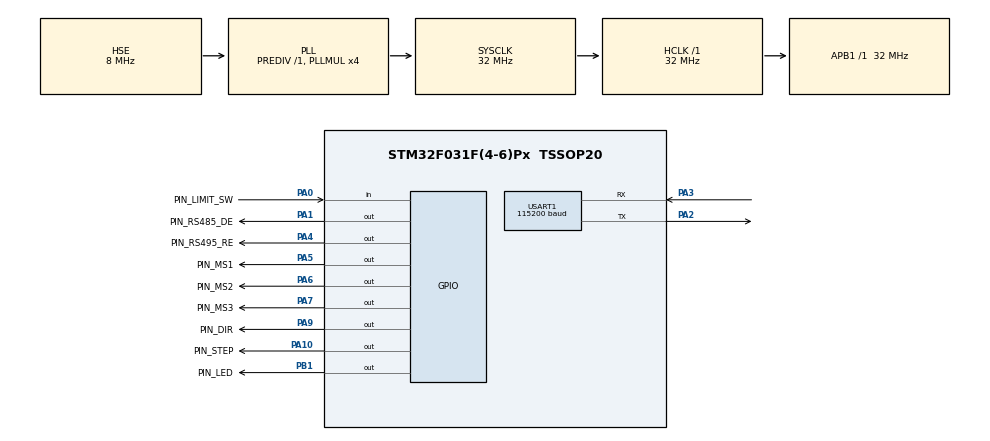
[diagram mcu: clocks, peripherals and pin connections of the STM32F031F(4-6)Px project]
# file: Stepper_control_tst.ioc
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Dma.Request0=USART1_RX
Dma.USART1_RX.0.Direction=DMA_PERIPH_TO_MEMORY
Dma.USART1_RX.0.Instance=DMA1_Channel3
Dma.USART1_RX.0.MemDataAlignment=DMA_MDATAALIGN_BYTE
Dma.USART1_RX.0.MemInc=DMA_MINC_ENABLE
Dma.USART1_RX.0.Mode=DMA_CIRCULAR
Dma.USART1_RX.0.PeriphDataAlignment=DMA_PDATAALIGN_BYTE
Dma.USART1_RX.0.PeriphInc=DMA_PINC_DISABLE
Dma.USART1_RX.0.Priority=DMA_PRIORITY_LOW
Mcu.Family=STM32F0
Mcu.Name=STM32F031F(4-6)Px
Mcu.Package=TSSOP20
NVIC.DMA1_Channel2_3_IRQn=true\:0\:0\:false\:false\:true\:false\:true\:true
NVIC.TIM2_IRQn=true\:0\:0\:false\:false\:true\:true\:true\:true
PA0.GPIO_Label=PIN_LIMIT_SW
PA0.Signal=GPIO_Input
PA1.GPIO_Label=PIN_RS485_DE
PA1.Signal=GPIO_Output
PA10.GPIO_Label=PIN_STEP
PA10.Signal=GPIO_Output
PA13.Mode=Serial_Wire
PA13.Signal=SYS_SWDIO
PA14.Mode=Serial_Wire
PA14.Signal=SYS_SWCLK
PA2.Mode=Asynchronous
PA2.Signal=USART1_TX
PA3.Mode=Asynchronous
PA3.Signal=USART1_RX
PA4.GPIO_Label=PIN_RS495_RE
PA4.Signal=GPIO_Output
PA5.GPIO_Label=PIN_MS1
PA5.Signal=GPIO_Output
PA6.GPIO_Label=PIN_MS2
PA6.Signal=GPIO_Output
PA7.GPIO_Label=PIN_MS3
PA7.Signal=GPIO_Output
PA9.GPIO_Label=PIN_DIR
PA9.Signal=GPIO_Output
PB1.GPIO_Label=PIN_LED
PB1.Signal=GPIO_Output
PF0-OSC_IN.Mode=HSE-External-Oscillator
PF0-OSC_IN.Signal=RCC_OSC_IN
PF1-OSC_OUT.Mode=HSE-External-Oscillator
PF1-OSC_OUT.Signal=RCC_OSC_OUT
ProjectManager.HeapSize=0x200
ProjectManager.StackSize=0x400
ProjectManager.TargetToolchain=STM32CubeIDE
RCC.AHBFreq_Value=32000000
RCC.APB1Freq_Value=32000000
RCC.APB1TimFreq_Value=32000000
RCC.HCLKFreq_Value=32000000
RCC.PLLMUL=RCC_PLL_MUL4
RCC.PLLSourceVirtual=RCC_PLLSOURCE_HSE
RCC.SYSCLKFreq_VALUE=32000000
RCC.SYSCLKSource=RCC_SYSCLKSOURCE_PLLCLK
TIM2.AutoReloadPreload=TIM_AUTORELOAD_PRELOAD_ENABLE
TIM2.Period=160
TIM2.Prescaler=100
USART1.BaudRate=115200
USART1.VirtualMode-Asynchronous=VM_ASYNC
VP_ADC_Vbat_Input.Mode=IN-Vbat
VP_TIM2_VS_ClockSourceINT.Mode=Internal
board=custom

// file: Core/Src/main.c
/* USER CODE BEGIN Header */
/**
  ******************************************************************************
  * @file           : main.c
  * @brief          : Main program body
  ******************************************************************************
  * @attention
  *
  * Copyright (c) 2023 STMicroelectronics.
  * All rights reserved.
  *
  * This software is licensed under terms that can be found in the LICENSE file
  * in the root directory of this software component.
  * If no LICENSE file comes with this software, it is provided AS-IS.
  *
  ******************************************************************************
  */
/* USER CODE END Header */
#include "main.h"

/* USER CODE BEGIN Includes */
#include <stdbool.h>

#include "cmd.h"
#include "stepper_control.h"
#include "debug_FZ.h"

/* USER CODE END Includes */

ADC_HandleTypeDef hadc;

TIM_HandleTypeDef htim2;

// UART_HandleTypeDef huart1;
DMA_HandleTypeDef hdma_usart1_rx;

void SystemClock_Config(void);
static void MX_GPIO_Init(void);
static void MX_DMA_Init(void);
// static void MX_USART1_UART_Init(void);
static void MX_ADC_Init(void);
static void MX_TIM2_Init(void);

int main(void)
{
  /* USER CODE BEGIN 1 */
    /* Reset of all peripherals, Initializes the Flash interface and the Systick. */
  HAL_Init();

  /* Configure the system clock */
  SystemClock_Config();

  /* Initialize all configured peripherals */
  MX_GPIO_Init();
  MX_DMA_Init();
  MX_USART1_UART_Init();
  MX_ADC_Init();
  MX_TIM2_Init();

  DMA_init();

  stepper_init(MICROSTEP_1_8);

  HAL_TIM_Base_Start_IT(&htim2);

  HAL_GPIO_WritePin(PIN_LED_GPIO_Port, PIN_LED_Pin, GPIO_PIN_SET);
  HAL_Delay(50);
  HAL_GPIO_WritePin(PIN_LED_GPIO_Port, PIN_LED_Pin, GPIO_PIN_RESET);

  /* Infinite loop */
  while (1)
  {
    Parse_CMD(CMD_recv);

  }
}

void SystemClock_Config(void)
{
  RCC_OscInitTypeDef RCC_OscInitStruct = {0};
  RCC_ClkInitTypeDef RCC_ClkInitStruct = {0};
  RCC_PeriphCLKInitTypeDef PeriphClkInit = {0};

  /** Initializes the RCC Oscillators according to the specified parameters
  * in the RCC_OscInitTypeDef structure.
  */
  RCC_OscInitStruct.OscillatorType = RCC_OSCILLATORTYPE_HSI14|RCC_OSCILLATORTYPE_HSE;
  RCC_OscInitStruct.HSEState = RCC_HSE_ON;
  RCC_OscInitStruct.HSI14State = RCC_HSI14_ON;
  RCC_OscInitStruct.HSI14CalibrationValue = 16;
  RCC_OscInitStruct.PLL.PLLState = RCC_PLL_ON;
  RCC_OscInitStruct.PLL.PLLSource = RCC_PLLSOURCE_HSE;
  RCC_OscInitStruct.PLL.PLLMUL = RCC_PLL_MUL4;
  RCC_OscInitStruct.PLL.PREDIV = RCC_PREDIV_DIV1;
  if (HAL_RCC_OscConfig(&RCC_OscInitStruct) != HAL_OK)
  {
    Error_Handler();
  }

  /** Initializes the CPU, AHB and APB buses clocks
  */
  RCC_ClkInitStruct.ClockType = RCC_CLOCKTYPE_HCLK|RCC_CLOCKTYPE_SYSCLK
                              |RCC_CLOCKTYPE_PCLK1;
  RCC_ClkInitStruct.SYSCLKSource = RCC_SYSCLKSOURCE_PLLCLK;
  RCC_ClkInitStruct.AHBCLKDivider = RCC_SYSCLK_DIV1;
  RCC_ClkInitStruct.APB1CLKDivider = RCC_HCLK_DIV1;

  if (HAL_RCC_ClockConfig(&RCC_ClkInitStruct, FLASH_LATENCY_1) != HAL_OK)
  {
    Error_Handler();
  }
  PeriphClkInit.PeriphClockSelection = RCC_PERIPHCLK_USART1;
  PeriphClkInit.Usart1ClockSelection = RCC_USART1CLKSOURCE_PCLK1;
  if (HAL_RCCEx_PeriphCLKConfig(&PeriphClkInit) != HAL_OK)
  {
    Error_Handler();
  }
}

static void MX_ADC_Init(void)
{

  ADC_ChannelConfTypeDef sConfig = {0};

  /** Configure the global features of the ADC (Clock, Resolution, Data Alignment and number of conversion)
  */
  hadc.Instance = ADC1;
  hadc.Init.ClockPrescaler = ADC_CLOCK_ASYNC_DIV1;
  hadc.Init.Resolution = ADC_RESOLUTION_12B;
  hadc.Init.DataAlign = ADC_DATAALIGN_RIGHT;
  hadc.Init.ScanConvMode = ADC_SCAN_DIRECTION_FORWARD;
  hadc.Init.EOCSelection = ADC_EOC_SINGLE_CONV;
  hadc.Init.LowPowerAutoWait = DISABLE;
  hadc.Init.LowPowerAutoPowerOff = DISABLE;
  hadc.Init.ContinuousConvMode = DISABLE;
  hadc.Init.DiscontinuousConvMode = DISABLE;
  hadc.Init.ExternalTrigConv = ADC_SOFTWARE_START;
  hadc.Init.ExternalTrigConvEdge = ADC_EXTERNALTRIGCONVEDGE_NONE;
  hadc.Init.DMAContinuousRequests = DISABLE;
  hadc.Init.Overrun = ADC_OVR_DATA_PRESERVED;
  if (HAL_ADC_Init(&hadc) != HAL_OK)
  {
    Error_Handler();
  }

  /** Configure for the selected ADC regular channel to be converted.
  */
  sConfig.Channel = ADC_CHANNEL_VBAT;
  sConfig.Rank = ADC_RANK_CHANNEL_NUMBER;
  sConfig.SamplingTime = ADC_SAMPLETIME_1CYCLE_5;
  if (HAL_ADC_ConfigChannel(&hadc, &sConfig) != HAL_OK)
  {
    Error_Handler();
  }

}

static void MX_TIM2_Init(void)
{

  TIM_ClockConfigTypeDef sClockSourceConfig = {0};
  TIM_MasterConfigTypeDef sMasterConfig = {0};

  htim2.Instance = TIM2;
  htim2.Init.Prescaler = 50;
  htim2.Init.CounterMode = TIM_COUNTERMODE_UP;
  htim2.Init.Period = 160;
  htim2.Init.ClockDivision = TIM_CLOCKDIVISION_DIV1;
  htim2.Init.AutoReloadPreload = TIM_AUTORELOAD_PRELOAD_ENABLE;
  if (HAL_TIM_Base_Init(&htim2) != HAL_OK) {
    Error_Handler();
  }

  sClockSourceConfig.ClockSource = TIM_CLOCKSOURCE_INTERNAL;

  if (HAL_TIM_ConfigClockSource(&htim2, &sClockSourceConfig) != HAL_OK) {
    Error_Handler();
  }

  sMasterConfig.MasterOutputTrigger = TIM_TRGO_RESET;
  sMasterConfig.MasterSlaveMode = TIM_MASTERSLAVEMODE_DISABLE;

  if (HAL_TIMEx_MasterConfigSynchronization(&htim2, &sMasterConfig) != HAL_OK) {
    Error_Handler();
  }

}

static void MX_DMA_Init(void)
{

  /* DMA controller clock enable */
  __HAL_RCC_DMA1_CLK_ENABLE();

  /* DMA interrupt init */
  /* DMA1_Channel2_3_IRQn interrupt configuration */
  HAL_NVIC_SetPriority(DMA1_Channel2_3_IRQn, 0, 0);
  HAL_NVIC_EnableIRQ(DMA1_Channel2_3_IRQn);

}

static void MX_GPIO_Init(void)
{
  GPIO_InitTypeDef GPIO_InitStruct = {0};

  /* GPIO Ports Clock Enable */
  __HAL_RCC_GPIOF_CLK_ENABLE();
  __HAL_RCC_GPIOA_CLK_ENABLE();
  __HAL_RCC_GPIOB_CLK_ENABLE();

  /*Configure GPIO pin Output Level */
  HAL_GPIO_WritePin(GPIOA, PIN_RS485_DE_Pin|PIN_RS495_RE_Pin|PIN_MS1_Pin|PIN_MS2_Pin
                          |PIN_MS3_Pin|PIN_DIR_Pin|PIN_STEP_Pin, GPIO_PIN_RESET);

  /*Configure GPIO pin Output Level */
  HAL_GPIO_WritePin(PIN_LED_GPIO_Port, PIN_LED_Pin, GPIO_PIN_RESET);

  /*Configure GPIO pin : PIN_LIMIT_SW_Pin */
  GPIO_InitStruct.Pin = PIN_LIMIT_SW_Pin;
  GPIO_InitStruct.Mode = GPIO_MODE_INPUT;
  GPIO_InitStruct.Pull = GPIO_NOPULL;
  HAL_GPIO_Init(PIN_LIMIT_SW_GPIO_Port, &GPIO_InitStruct);

  /*Configure GPIO pins : PIN_RS485_DE_Pin PIN_RS495_RE_Pin PIN_MS1_Pin PIN_MS2_Pin
                           PIN_MS3_Pin PIN_DIR_Pin PIN_STEP_Pin */
  GPIO_InitStruct.Pin = PIN_RS485_DE_Pin|PIN_RS495_RE_Pin|PIN_MS1_Pin|PIN_MS2_Pin
                          |PIN_MS3_Pin|PIN_DIR_Pin|PIN_STEP_Pin;
  GPIO_InitStruct.Mode = GPIO_MODE_OUTPUT_PP;
  GPIO_InitStruct.Pull = GPIO_NOPULL;
  GPIO_InitStruct.Speed = GPIO_SPEED_FREQ_LOW;
  HAL_GPIO_Init(GPIOA, &GPIO_InitStruct);

  /*Configure GPIO pin : PIN_LED_Pin */
  GPIO_InitStruct.Pin = PIN_LED_Pin;
  GPIO_InitStruct.Mode = GPIO_MODE_OUTPUT_PP;
  GPIO_InitStruct.Pull = GPIO_NOPULL;
  GPIO_InitStruct.Speed = GPIO_SPEED_FREQ_LOW;
  HAL_GPIO_Init(PIN_LED_GPIO_Port, &GPIO_InitStruct);

}

void Error_Handler(void)
{
  __disable_irq();
  while (1) {
  }
}
